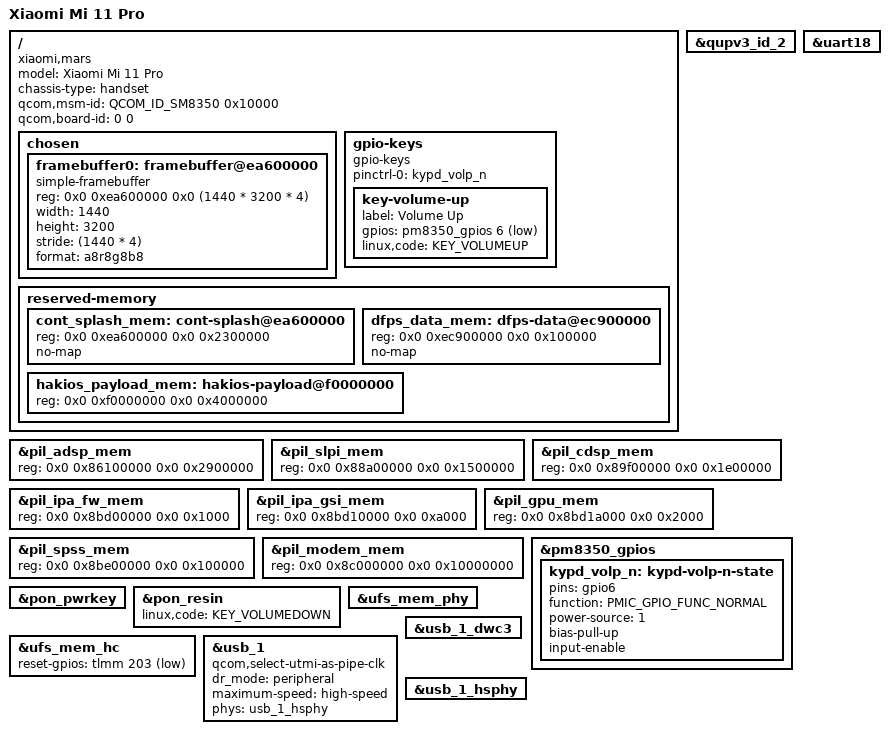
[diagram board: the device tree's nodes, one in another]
// SPDX-License-Identifier: BSD-3-Clause
/*
 * The Xiaomi Mi 11 Pro (mars, SM8350) for HakiOS's U-Boot.
 *
 * Only what U-Boot needs: the memory the firmware and the remote processors keep, the panel's framebuffer as the
 * bootloader left it, the keys, USB as a device (fastboot) and UFS. Every address is the phone's own: the reserved
 * memory is the Android device tree's (devices/mars/vendor_0.dtb, the Lahaina V2.1 tree) and Silicium's memory map,
 * whichever reserves more.
 *
 * The size of RAM is not here: ABL writes it into the device tree it hands over (the appended Android one), and U-Boot
 * reads it from there (arch/arm/mach-snapdragon/board.c, qcom_parse_memory()).
 */

/dts-v1/;

#include <dt-bindings/arm/qcom,ids.h>
#include <dt-bindings/gpio/gpio.h>
#include <dt-bindings/input/linux-event-codes.h>
#include <dt-bindings/pinctrl/qcom,pmic-gpio.h>
#include "sm8350.dtsi"
#include "pm8350.dtsi"
#include "pm8350c.dtsi"
#include "pmk8350.dtsi"

/* The Bluetooth half of the WCN6855 sits on QUPv3 wrapper 2, SE 4 (0x890000). The vendor's own tree keeps it
   off; U-Boot is asked to bring it up so the chip can be spoken to before anything else runs. */
&qupv3_id_2 {
	/* U-Boot has no SMMU for this wrapper to point at: its own dev_iommu_enable() fails with -19 and
	   the wrapper then never probes ("GENI-SE: GENI SE wrapper not found"), which leaves the Bluetooth
	   UART inside it unreachable. Nothing here does DMA through an IOMMU. */
	/delete-property/ iommus;
	status = "okay";
};

&uart18 {
	status = "okay";
};


/*
 * kodiak.dtsi's carve-outs are a Chromebook's; the phone's differ (below). Its rmtfs and ADSP RPC heap fall inside the
 * phone's CDSP image and pil_mem, which reserve them anyway.
 */
/delete-node/ &rmtfs_mem;

/ {
	model = "Xiaomi Mi 11 Pro";
	compatible = "xiaomi,mars", "qcom,sm8350";
	chassis-type = "handset";

	/* what ABL matches against; the appended Android device tree carries the same */
	qcom,msm-id = <QCOM_ID_SM8350 0x10000>;
	qcom,board-id = <0 0>;

	chosen {
		#address-cells = <2>;
		#size-cells = <2>;
		ranges;

		/*
		 * The panel as ABL left it: 1440 x 3200, 32 bits. At 0xEA600000 the HakiOS loader knows the phone by it
		 * (xnuloader/loader.c, efi_main()). No clocks: U-Boot keeps the display running by not touching it.
		 */
		framebuffer0: framebuffer@ea600000 {
			compatible = "simple-framebuffer";
			reg = <0x0 0xea600000 0x0 (1440 * 3200 * 4)>;
			width = <1440>;
			height = <3200>;
			stride = <(1440 * 4)>;
			format = "a8r8g8b8";
		};
	};

	gpio-keys {
		compatible = "gpio-keys";

		pinctrl-0 = <&kypd_volp_n>;
		pinctrl-names = "default";

		key-volume-up {
			label = "Volume Up";
			gpios = <&pm8350_gpios 6 GPIO_ACTIVE_LOW>;
			linux,code = <KEY_VOLUMEUP>;
		};
	};

	reserved-memory {
		/* the Android device tree's, where kodiak.dtsi has other addresses or nothing */
		/* the panel's memory and the display's dfps data after it */
		cont_splash_mem: cont-splash@ea600000 {
			reg = <0x0 0xea600000 0x0 0x2300000>;
			no-map;
		};

		dfps_data_mem: dfps-data@ec900000 {
			reg = <0x0 0xec900000 0x0 0x100000>;
			no-map;
		};

		/*
		 * Where the HakiOS loader takes its payload from (PAYLOAD_BASE, 64 MiB with the panic log in its last MiB).
		 * Mapped (no no-map): the hakios command writes the payload here, and nothing else in U-Boot may take it.
		 */
		hakios_payload_mem: hakios-payload@f0000000 {
			reg = <0x0 0xf0000000 0x0 0x4000000>;
		};
	};
};

/* the sm8350.dtsi's pil nodes, where they differ from mars's own tree */
/*
 * The audio DSP's image goes here (drivers/audio/hakios.adsp.c, adsp_memory=0x86100000): the Lahaina
 * image's own addresses start at 0x87300000 and its span is 57 MB. Upstream's 33 MB end at 0x88200000,
 * 8 MB short of pil_slpi_mem where this file moves it -- memory the kernel would hand out and the
 * image would then overwrite -- so the vendor's own 41 MB, which ends where the slpi's region begins.
 * The image is 57 MB, so its last 16 MB lie in the slpi's region, which this boot does not load either.
 */
&pil_adsp_mem {
	reg = <0x0 0x86100000 0x0 0x2900000>;
};

&pil_slpi_mem {
	reg = <0x0 0x88a00000 0x0 0x1500000>;
};

&pil_cdsp_mem {
	reg = <0x0 0x89f00000 0x0 0x1e00000>;
};

&pil_ipa_fw_mem {
	reg = <0x0 0x8bd00000 0x0 0x1000>;
};

&pil_ipa_gsi_mem {
	reg = <0x0 0x8bd10000 0x0 0xa000>;
};

&pil_gpu_mem {
	reg = <0x0 0x8bd1a000 0x0 0x2000>;
};

&pil_spss_mem {
	reg = <0x0 0x8be00000 0x0 0x100000>;
};

&pil_modem_mem {
	reg = <0x0 0x8c000000 0x0 0x10000000>;
};

&pm8350_gpios {
	kypd_volp_n: kypd-volp-n-state {
		pins = "gpio6";
		function = PMIC_GPIO_FUNC_NORMAL;
		power-source = <1>;
		bias-pull-up;
		input-enable;
	};
};

&pon_pwrkey {
	status = "okay";
};

&pon_resin {
	linux,code = <KEY_VOLUMEDOWN>;
	status = "okay";
};

&ufs_mem_hc {
	reset-gpios = <&tlmm 203 GPIO_ACTIVE_LOW>;
	status = "okay";
};

&ufs_mem_phy {
	status = "okay";
};

/* USB 2.0 as a device: U-Boot's fastboot; the SuperSpeed PHY is left as ABL left it */
&usb_1 {
	/*
	 * No power domain and no reset: U-Boot's dwc3 asks the wrapper for them, and
	 * this phone's U-Boot has no power-domain driver to answer
	 * ("dwc3-generic-wrapper usb@a6f8800: power-domain driver not found"): the
	 * probe failed with -19 and the loader never got a USB device controller.
	 */
	/delete-property/ power-domains;
	/delete-property/ resets;
	qcom,select-utmi-as-pipe-clk;
	dr_mode = "peripheral";
	maximum-speed = "high-speed";
	phys = <&usb_1_hsphy>;
	phy-names = "usb2-phy";
	status = "okay";
};

/*
 * And no IOMMU on the controller itself: dev_iommu_enable() looks up the SMMU
 * this node names (the phone's own tree gives <&apps_smmu 0x00 0x00>) and finds
 * nothing bound to it, so the probe failed with -19 again.  A fastboot transfer
 * needs no IOMMU.
 */
&usb_1_dwc3 {
	/delete-property/ iommus;
};

&usb_1_hsphy {
	status = "okay";
};
